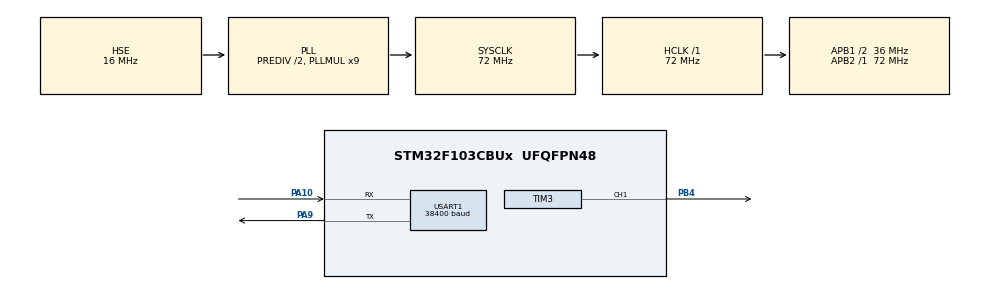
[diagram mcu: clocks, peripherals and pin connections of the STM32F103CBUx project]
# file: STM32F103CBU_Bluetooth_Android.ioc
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Dma.Request0=TIM3_CH1/TRIG
Dma.Request1=USART1_RX
Dma.Request2=USART1_TX
Dma.TIM3_CH1/TRIG.0.Direction=DMA_MEMORY_TO_PERIPH
Dma.TIM3_CH1/TRIG.0.Instance=DMA1_Channel6
Dma.TIM3_CH1/TRIG.0.MemDataAlignment=DMA_MDATAALIGN_HALFWORD
Dma.TIM3_CH1/TRIG.0.MemInc=DMA_MINC_ENABLE
Dma.TIM3_CH1/TRIG.0.Mode=DMA_NORMAL
Dma.TIM3_CH1/TRIG.0.PeriphDataAlignment=DMA_PDATAALIGN_HALFWORD
Dma.TIM3_CH1/TRIG.0.PeriphInc=DMA_PINC_DISABLE
Dma.TIM3_CH1/TRIG.0.Priority=DMA_PRIORITY_LOW
Dma.USART1_RX.1.Direction=DMA_PERIPH_TO_MEMORY
Dma.USART1_RX.1.Instance=DMA1_Channel5
Dma.USART1_RX.1.MemDataAlignment=DMA_MDATAALIGN_BYTE
Dma.USART1_RX.1.MemInc=DMA_MINC_ENABLE
Dma.USART1_RX.1.Mode=DMA_CIRCULAR
Dma.USART1_RX.1.PeriphDataAlignment=DMA_PDATAALIGN_BYTE
Dma.USART1_RX.1.PeriphInc=DMA_PINC_DISABLE
Dma.USART1_RX.1.Priority=DMA_PRIORITY_LOW
Dma.USART1_TX.2.Direction=DMA_MEMORY_TO_PERIPH
Dma.USART1_TX.2.Instance=DMA1_Channel4
Dma.USART1_TX.2.MemDataAlignment=DMA_MDATAALIGN_BYTE
Dma.USART1_TX.2.MemInc=DMA_MINC_ENABLE
Dma.USART1_TX.2.Mode=DMA_NORMAL
Dma.USART1_TX.2.PeriphDataAlignment=DMA_PDATAALIGN_BYTE
Dma.USART1_TX.2.PeriphInc=DMA_PINC_DISABLE
Dma.USART1_TX.2.Priority=DMA_PRIORITY_LOW
Mcu.Family=STM32F1
Mcu.Name=STM32F103CBUx
Mcu.Package=UFQFPN48
NVIC.DMA1_Channel4_IRQn=true\:0\:0\:false\:false\:true\:false\:true\:true
NVIC.DMA1_Channel5_IRQn=true\:0\:0\:false\:false\:true\:false\:true\:true
NVIC.DMA1_Channel6_IRQn=true\:0\:0\:false\:false\:true\:false\:true\:true
NVIC.PriorityGroup=NVIC_PRIORITYGROUP_4
NVIC.USART1_IRQn=true\:0\:0\:false\:false\:true\:true\:true\:true
PA10.Mode=Asynchronous
PA10.Signal=USART1_RX
PA13.Mode=Serial_Wire
PA13.Signal=SYS_JTMS-SWDIO
PA14.Mode=Serial_Wire
PA14.Signal=SYS_JTCK-SWCLK
PA9.Mode=Asynchronous
PA9.Signal=USART1_TX
PB4.Signal=S_TIM3_CH1
PD0-OSC_IN.Mode=HSE-External-Oscillator
PD0-OSC_IN.Signal=RCC_OSC_IN
PD1-OSC_OUT.Mode=HSE-External-Oscillator
PD1-OSC_OUT.Signal=RCC_OSC_OUT
ProjectManager.HeapSize=0x200
ProjectManager.StackSize=0x400
ProjectManager.TargetToolchain=STM32CubeIDE
RCC.AHBFreq_Value=72000000
RCC.APB1CLKDivider=RCC_HCLK_DIV2
RCC.APB1Freq_Value=36000000
RCC.APB1TimFreq_Value=72000000
RCC.APB2Freq_Value=72000000
RCC.APB2TimFreq_Value=72000000
RCC.HCLKFreq_Value=72000000
RCC.HSEDivPLL=RCC_HSE_PREDIV_DIV2
RCC.HSE_VALUE=16000000
RCC.PLLMUL=RCC_PLL_MUL9
RCC.PLLSourceVirtual=RCC_PLLSOURCE_HSE
RCC.SYSCLKFreq_VALUE=72000000
RCC.SYSCLKSource=RCC_SYSCLKSOURCE_PLLCLK
RCC.USBFreq_Value=72000000
SH.S_TIM3_CH1.0=TIM3_CH1,PWM Generation1 CH1
TIM3.Channel-PWM\ Generation1\ CH1=TIM_CHANNEL_1
TIM3.Period=90-1
USART1.BaudRate=38400
USART1.VirtualMode=VM_ASYNC
board=custom

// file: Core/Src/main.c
/* USER CODE BEGIN Header */
/**
  ******************************************************************************
  * @file           : main.c
  * @brief          : Main program body
  ******************************************************************************
  * @attention
  *
  * Copyright (c) 2022 STMicroelectronics.
  * All rights reserved.
  *
  * This software is licensed under terms that can be found in the LICENSE file
  * in the root directory of this software component.
  * If no LICENSE file comes with this software, it is provided AS-IS.
  *
  ******************************************************************************
  */
/* USER CODE END Header */
#include "main.h"

/* USER CODE BEGIN Includes */

#include "math.h"
#include "string.h"
#include <stdlib.h>
#include <stdio.h>
/* USER CODE END Includes */

TIM_HandleTypeDef htim3;
DMA_HandleTypeDef hdma_tim3_ch1_trig;

UART_HandleTypeDef huart1;
DMA_HandleTypeDef hdma_usart1_rx;
DMA_HandleTypeDef hdma_usart1_tx;

void SystemClock_Config(void);
static void MX_GPIO_Init(void);
static void MX_DMA_Init(void);
static void MX_USART1_UART_Init(void);
static void MX_TIM3_Init(void);

/* USER CODE BEGIN 0 */
#define MAX_LED 24
#define USE_BRIGHTNESS 1
#define PI 3.14159265
int datasentflag=0;
uint16_t effStep = 1;
uint8_t LED_Data[MAX_LED][8];
uint8_t LED_Mod[MAX_LED][8];  // for brightness
uint8_t RxBuf[1];
uint8_t MainBuf[1];
uint16_t pwmData[(24*MAX_LED)+50];

char eff1[] = {'A'};
char *ptr1 = eff1;
char eff2[] = {'B'};
char *ptr2 = eff2;
char eff3[] = {'C'};
char *ptr3 = eff3;

int val = 0;
int eff = 0;

void HAL_TIM_PWM_PulseFinishedCallback(TIM_HandleTypeDef *htim)
{
	HAL_TIM_PWM_Stop_DMA(&htim3, TIM_CHANNEL_1);
	datasentflag=1;
}

void Set_LED (int LEDnum, int Red, int Green, int Blue)
{
	LED_Data[LEDnum][0] = LEDnum;
	LED_Data[LEDnum][1] = Green;
	LED_Data[LEDnum][2] = Red;
	LED_Data[LEDnum][3] = Blue;
}

static void Set_Brightness (int brightness)  // 0-45
{
#if USE_BRIGHTNESS
	if (brightness > 45) brightness = 45;
	for (int i=0; i<MAX_LED; i++)
	{
		LED_Mod[i][0] = LED_Data[i][0];
		for (int j=1; j<4; j++)
		{
			float angle = 90-brightness;  // in degrees
			angle = angle*PI / 180;  // in rad
			LED_Mod[i][j] = (LED_Data[i][j])/(tan(angle));
		}
	}

#endif
}

static void WS2812_Send (void)
	{
		uint32_t indx=0;
		uint32_t color;
		for (int i= 0; i<MAX_LED; i++)
		{
	#if USE_BRIGHTNESS
			color = ((LED_Mod[i][1]<<16) | (LED_Mod[i][2]<<8) | (LED_Mod[i][3]));
	#else
			color = ((LED_Data[i][1]<<16) | (LED_Data[i][2]<<8) | (LED_Data[i][3]));
	#endif

			for (int i=23; i>=0; i--)
			{
				if (color&(1<<i))
				{
					pwmData[indx] = 60;  // 2/3 of 90
				}
				else pwmData[indx] = 30;  // 1/3 of 90
				indx++;
			}
		}
		for (int i=0; i<50; i++)
		{
			pwmData[indx] = 0;
			indx++;
		}

		HAL_TIM_PWM_Start_DMA(&htim3, TIM_CHANNEL_1, (uint32_t *)pwmData, indx);
		while (!datasentflag){};
		datasentflag = 0;
	}

void Reset_LED (void)
	{
		for (int i=0; i<MAX_LED; i++)
		{
			LED_Data[i][0] = i;
			LED_Data[i][1] = 0;
			LED_Data[i][2] = 0;
			LED_Data[i][3] = 0;
		}
	}

static uint8_t rainbow_effect_left() {
	    // Strip ID: 0 - Effect: Rainbow - LEDS: 8
	    // Steps: 13 - Delay: 54
	    // Colors: 3 (255.0.0, 0.255.0, 0.0.255)
	    // Options: rainbowlen=8, toLeft=true,
	  //if(millis() - strip_0.effStart < 54 * (strip_0.effStep)) return 0x00;

	  float factor1, factor2;
	  uint16_t ind;
	  for(uint16_t j=0;j<24;j++) {
	    ind = effStep + j * 1.625;
	    switch((int)((ind % 13) / 4.333333333333333)) {
	      case 0: factor1 = 1.0 - ((float)(ind % 13 - 0 * 4.333333333333333) / 4.333333333333333);
	              factor2 = (float)((int)(ind - 0) % 13) / 4.333333333333333;
	              /************ chnaged here *********/
	              Set_LED(j, 255 * factor1 + 0 * factor2, 0 * factor1 + 255 * factor2, 0 * factor1 + 0 * factor2);
	              WS2812_Send();
	              break;
	      case 1: factor1 = 1.0 - ((float)(ind % 13 - 1 * 4.333333333333333) / 4.333333333333333);
	              factor2 = (float)((int)(ind - 4.333333333333333) % 13) / 4.333333333333333;
	              Set_LED(j, 0 * factor1 + 0 * factor2, 255 * factor1 + 0 * factor2, 0 * factor1 + 255 * factor2);
	              WS2812_Send();
	              break;
	      case 2: factor1 = 1.0 - ((float)(ind % 13 - 2 * 4.333333333333333) / 4.333333333333333);
	              factor2 = (float)((int)(ind - 8.666666666666666) % 13) / 4.333333333333333;
	              Set_LED(j, 0 * factor1 + 255 * factor2, 0 * factor1 + 0 * factor2, 255 * factor1 + 0 * factor2);
	              WS2812_Send();
	              break;
	    }
	  }
	  if(effStep >= 13) {effStep=0; return 0x03; }
	  else effStep++;
	  return 0x01;
	}

static uint8_t rainbow_effect_right() {
	    // Strip ID: 0 - Effect: Rainbow - LEDS: 8
	    // Steps: 14 - Delay: 30
	    // Colors: 3 (255.0.0, 0.255.0, 0.0.255)
	    // Options: rainbowlen=8, toLeft=false,
	//  if(millis() - strip_0.effStart < 30 * (strip_0.effStep)) return 0x00;
	  float factor1, factor2;
	  uint16_t ind;
	  for(uint16_t j=0;j<24;j++) {
	    ind = 14 - (int16_t)(effStep - j * 1.75) % 14;
	    switch((int)((ind % 14) / 4.666666666666667)) {
	      case 0: factor1 = 1.0 - ((float)(ind % 14 - 0 * 4.666666666666667) / 4.666666666666667);
	              factor2 = (float)((int)(ind - 0) % 14) / 4.666666666666667;
	              Set_LED(j, 255 * factor1 + 0 * factor2, 0 * factor1 + 255 * factor2, 0 * factor1 + 0 * factor2);
	              WS2812_Send();
	              break;
	    	  factor1 = 1.0 - ((float)(ind % 14 - 2 * 4.666666666666667) / 4.666666666666667);
	    	  	              factor2 = (float)((int)(ind - 9.333333333333334) % 14) / 4.666666666666667;
	    	  	              Set_LED(j, 0 * factor1 + 255 * factor2, 0 * factor1 + 0 * factor2, 255 * factor1 + 0 * factor2);
	    	  	              WS2812_Send();
	    	  	              break;

	      case 1: factor1 = 1.0 - ((float)(ind % 14 - 1 * 4.666666666666667) / 4.666666666666667);
	              factor2 = (float)((int)(ind - 4.666666666666667) % 14) / 4.666666666666667;
	              Set_LED(j, 0 * factor1 + 0 * factor2, 255 * factor1 + 0 * factor2, 0 * factor1 + 255 * factor2);
	              WS2812_Send();
	              break;
	      case 2: factor1 = 1.0 - ((float)(ind % 14 - 2 * 4.666666666666667) / 4.666666666666667);
	              factor2 = (float)((int)(ind - 9.333333333333334) % 14) / 4.666666666666667;
	              Set_LED(j, 0 * factor1 + 255 * factor2, 0 * factor1 + 0 * factor2, 255 * factor1 + 0 * factor2);
	              WS2812_Send();
	              break;
	    }
	  }
	  if(effStep >= 14) {effStep = 0; return 0x03; }
	  else effStep++;
	  return 0x01;
	}

static void white_effect (void){
		for(uint8_t j=0;j<24;j++) {
		  Set_LED(j, 255, 255, 255);
		  WS2812_Send();
		}
	}

/*void helligkeit (void)
  {
	  if (*rx_Data>=0 && *rx_Data<=45){
		  *rx_Data = hell;
	  	Set_Brightness(*rx_Data);
	  }
  }*/
/* USER CODE END 0 */

int main(void)
{

  /* MCU Configuration--------------------------------------------------------*/

  /* Reset of all peripherals, Initializes the Flash interface and the Systick. */
  HAL_Init();

  /* Configure the system clock */
  SystemClock_Config();

  /* Initialize all configured peripherals */
  MX_GPIO_Init();
  MX_DMA_Init();
  MX_USART1_UART_Init();
  MX_TIM3_Init();
  /* USER CODE BEGIN 2 */

  HAL_UART_Receive_DMA(&huart1, RxBuf, 1);
  HAL_UART_Receive_DMA(&huart1, MainBuf, 1);
  /* USER CODE END 2 */

  /* Infinite loop */
  while (1)
  {

    /* USER CODE BEGIN 3 */
    HAL_UART_Receive_DMA(&huart1, RxBuf, 1);
    switch (*RxBuf){
		case 0 ... 45:

		    rainbow_effect_left();
	        val = *RxBuf;
		    Set_Brightness(val);
		    //HAL_UART_Transmit_DMA(&huart1,(uint8_t*)ptr1, 1);
		    //HAL_UART_Transmit(&huart1, (uint8_t*)ptr1, 1, 100);
            HAL_Delay(1);
			break;

		case 50 ... 95:
		    rainbow_effect_right();
		    val = *RxBuf -50;
			Set_Brightness(val);
			 //HAL_UART_Transmit_DMA(&huart1,(uint8_t*)ptr2, 1);
			 //HAL_UART_Transmit(&huart1, (uint8_t*)ptr2, 1, 100);
			 HAL_Delay(1);
			break;

		case 100 ... 145:
		    white_effect();
		    val = *RxBuf -100;
			Set_Brightness(val);
			//HAL_UART_Transmit_DMA(&huart1,(uint8_t*)ptr3, 1);
			//HAL_UART_Transmit(&huart1, (uint8_t*)ptr3, 1, 100);
			HAL_Delay(1);
			break;
	}
  }
  /* USER CODE END 3 */
}

void SystemClock_Config(void)
{
  RCC_OscInitTypeDef RCC_OscInitStruct = {0};
  RCC_ClkInitTypeDef RCC_ClkInitStruct = {0};

  /** Initializes the RCC Oscillators according to the specified parameters
  * in the RCC_OscInitTypeDef structure.
  */
  RCC_OscInitStruct.OscillatorType = RCC_OSCILLATORTYPE_HSE;
  RCC_OscInitStruct.HSEState = RCC_HSE_ON;
  RCC_OscInitStruct.HSEPredivValue = RCC_HSE_PREDIV_DIV2;
  RCC_OscInitStruct.HSIState = RCC_HSI_ON;
  RCC_OscInitStruct.PLL.PLLState = RCC_PLL_ON;
  RCC_OscInitStruct.PLL.PLLSource = RCC_PLLSOURCE_HSE;
  RCC_OscInitStruct.PLL.PLLMUL = RCC_PLL_MUL9;
  if (HAL_RCC_OscConfig(&RCC_OscInitStruct) != HAL_OK)
  {
    Error_Handler();
  }

  /** Initializes the CPU, AHB and APB buses clocks
  */
  RCC_ClkInitStruct.ClockType = RCC_CLOCKTYPE_HCLK|RCC_CLOCKTYPE_SYSCLK
                              |RCC_CLOCKTYPE_PCLK1|RCC_CLOCKTYPE_PCLK2;
  RCC_ClkInitStruct.SYSCLKSource = RCC_SYSCLKSOURCE_PLLCLK;
  RCC_ClkInitStruct.AHBCLKDivider = RCC_SYSCLK_DIV1;
  RCC_ClkInitStruct.APB1CLKDivider = RCC_HCLK_DIV2;
  RCC_ClkInitStruct.APB2CLKDivider = RCC_HCLK_DIV1;

  if (HAL_RCC_ClockConfig(&RCC_ClkInitStruct, FLASH_LATENCY_2) != HAL_OK)
  {
    Error_Handler();
  }
}

static void MX_TIM3_Init(void)
{

  TIM_MasterConfigTypeDef sMasterConfig = {0};
  TIM_OC_InitTypeDef sConfigOC = {0};

  htim3.Instance = TIM3;
  htim3.Init.Prescaler = 0;
  htim3.Init.CounterMode = TIM_COUNTERMODE_UP;
  htim3.Init.Period = 90-1;
  htim3.Init.ClockDivision = TIM_CLOCKDIVISION_DIV1;
  htim3.Init.AutoReloadPreload = TIM_AUTORELOAD_PRELOAD_DISABLE;
  if (HAL_TIM_PWM_Init(&htim3) != HAL_OK)
  {
    Error_Handler();
  }
  sMasterConfig.MasterOutputTrigger = TIM_TRGO_RESET;
  sMasterConfig.MasterSlaveMode = TIM_MASTERSLAVEMODE_DISABLE;
  if (HAL_TIMEx_MasterConfigSynchronization(&htim3, &sMasterConfig) != HAL_OK)
  {
    Error_Handler();
  }
  sConfigOC.OCMode = TIM_OCMODE_PWM1;
  sConfigOC.Pulse = 0;
  sConfigOC.OCPolarity = TIM_OCPOLARITY_HIGH;
  sConfigOC.OCFastMode = TIM_OCFAST_DISABLE;
  if (HAL_TIM_PWM_ConfigChannel(&htim3, &sConfigOC, TIM_CHANNEL_1) != HAL_OK)
  {
    Error_Handler();
  }
  HAL_TIM_MspPostInit(&htim3);

}

static void MX_USART1_UART_Init(void)
{

  huart1.Instance = USART1;
  huart1.Init.BaudRate = 38400;
  huart1.Init.WordLength = UART_WORDLENGTH_8B;
  huart1.Init.StopBits = UART_STOPBITS_1;
  huart1.Init.Parity = UART_PARITY_NONE;
  huart1.Init.Mode = UART_MODE_TX_RX;
  huart1.Init.HwFlowCtl = UART_HWCONTROL_NONE;
  huart1.Init.OverSampling = UART_OVERSAMPLING_16;
  if (HAL_UART_Init(&huart1) != HAL_OK)
  {
    Error_Handler();
  }

}

static void MX_DMA_Init(void)
{

  /* DMA controller clock enable */
  __HAL_RCC_DMA1_CLK_ENABLE();

  /* DMA interrupt init */
  /* DMA1_Channel4_IRQn interrupt configuration */
  HAL_NVIC_SetPriority(DMA1_Channel4_IRQn, 0, 0);
  HAL_NVIC_EnableIRQ(DMA1_Channel4_IRQn);
  /* DMA1_Channel5_IRQn interrupt configuration */
  HAL_NVIC_SetPriority(DMA1_Channel5_IRQn, 0, 0);
  HAL_NVIC_EnableIRQ(DMA1_Channel5_IRQn);
  /* DMA1_Channel6_IRQn interrupt configuration */
  HAL_NVIC_SetPriority(DMA1_Channel6_IRQn, 0, 0);
  HAL_NVIC_EnableIRQ(DMA1_Channel6_IRQn);

}

static void MX_GPIO_Init(void)
{

  /* GPIO Ports Clock Enable */
  __HAL_RCC_GPIOD_CLK_ENABLE();
  __HAL_RCC_GPIOA_CLK_ENABLE();
  __HAL_RCC_GPIOB_CLK_ENABLE();

}

/* USER CODE BEGIN 4 */
/*void HAL_UART_RxCpltCallback(UART_HandleTypeDef *huart)
{
	switch (eff) {
		case 1:
			HAL_UART_Transmit_DMA(&huart1, eff1, 1);
			break;
		case 2:
			HAL_UART_Transmit_DMA(&huart1, eff2, 1);
			break;
		case 3:
			HAL_UART_Transmit_DMA(&huart1, eff3, 1);
			break;
	}

	HAL_UART_Receive_DMA(&huart1, RxBuf, 1);
}*/
/* USER CODE END 4 */

void Error_Handler(void)
{
  __disable_irq();
  while (1)
  {
  }
}
